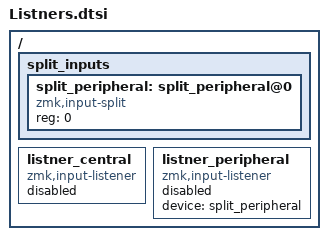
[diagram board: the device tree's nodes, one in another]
/{
  split_inputs {
    #address-cells = <1>;
    #size-cells = <0>;
    
    split_peripheral: split_peripheral@0 {
      compatible = "zmk,input-split";
      reg = <0>;
    };
  };
    
  listner_central: listner_central {
    compatible = "zmk,input-listener";
    status = "disabled";
  };
    
  listner_peripheral: listner_peripheral {
    compatible = "zmk,input-listener";
    device = <&split_peripheral>;
    status = "disabled";
  };
    
};
